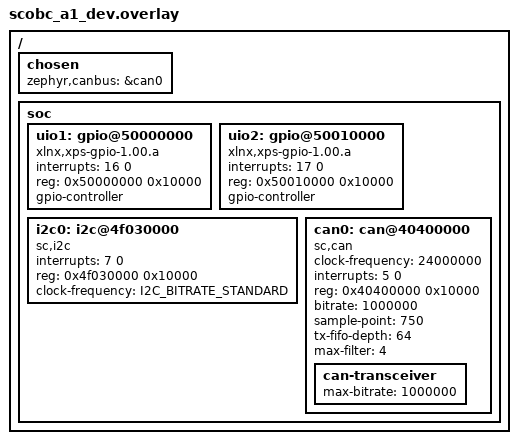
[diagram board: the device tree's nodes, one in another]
#include <zephyr/dt-bindings/gpio/gpio.h>
#include <zephyr/dt-bindings/i2c/i2c.h>
#include <zephyr/dt-bindings/input/input-event-codes.h>

/ {
	chosen {
		zephyr,canbus = &can0;
	};

	soc {
		uio1: gpio@50000000 {
			compatible = "xlnx,xps-gpio-1.00.a";
			interrupts = <16 0>;
			reg = <0x50000000 0x10000>;
			gpio-controller;
			#gpio-cells = <2>;
		};

		uio2: gpio@50010000 {
			compatible = "xlnx,xps-gpio-1.00.a";
			interrupts = <17 0>;
			reg = <0x50010000 0x10000>;
			gpio-controller;
			#gpio-cells = <2>;
		};

		i2c0: i2c@4f030000 {
			compatible = "sc,i2c";
			interrupts = <7 0>;
			reg = <0x4f030000 0x10000>;
			#address-cells = <1>;
			#size-cells = <0>;
			clock-frequency = <I2C_BITRATE_STANDARD>;
		};

		can0: can@40400000 {
			compatible = "sc,can";
			clock-frequency = <24000000>;
			interrupts = <5 0>;
			reg = <0x40400000 0x10000>;
			bitrate = <1000000>;
			sample-point = <750>;
			tx-fifo-depth = <64>;
			max-filter = <4>;

			can-transceiver {
				max-bitrate = <1000000>;
			};
		};
	};
};
